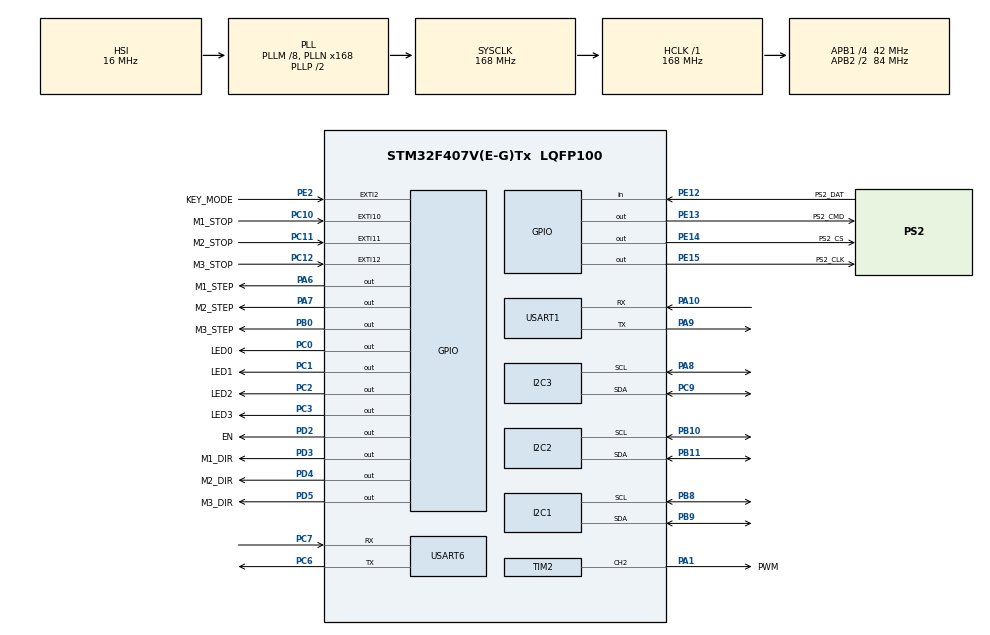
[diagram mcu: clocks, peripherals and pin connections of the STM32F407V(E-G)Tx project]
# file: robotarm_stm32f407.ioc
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I2C1.I2C_Mode=I2C_Standard
I2C2.I2C_Mode=I2C_Standard
I2C3.I2C_Mode=I2C_Standard
Mcu.Family=STM32F4
Mcu.Name=STM32F407V(E-G)Tx
Mcu.Package=LQFP100
NVIC.EXTI15_10_IRQn=true\:0\:0\:false\:false\:true\:true\:true\:true
NVIC.EXTI2_IRQn=true\:0\:0\:false\:false\:true\:true\:true\:true
NVIC.PriorityGroup=NVIC_PRIORITYGROUP_4
NVIC.TIM6_DAC_IRQn=true\:0\:0\:false\:false\:true\:true\:true\:true
NVIC.USART1_IRQn=true\:0\:0\:false\:false\:true\:true\:true\:true
PA1.GPIO_Label=PWM
PA1.Signal=S_TIM2_CH2
PA10.Mode=Asynchronous
PA10.Signal=USART1_RX
PA13.Mode=Serial_Wire
PA13.Signal=SYS_JTMS-SWDIO
PA14.Mode=Serial_Wire
PA14.Signal=SYS_JTCK-SWCLK
PA6.GPIO_Label=M1_STEP
PA6.GPIO_Speed=GPIO_SPEED_FREQ_VERY_HIGH
PA6.Signal=GPIO_Output
PA7.GPIO_Label=M2_STEP
PA7.GPIO_Speed=GPIO_SPEED_FREQ_VERY_HIGH
PA7.Signal=GPIO_Output
PA8.GPIO_Pu=GPIO_PULLUP
PA8.Mode=I2C
PA8.Signal=I2C3_SCL
PA9.Mode=Asynchronous
PA9.Signal=USART1_TX
PB0.GPIO_Label=M3_STEP
PB0.GPIO_Speed=GPIO_SPEED_FREQ_VERY_HIGH
PB0.Signal=GPIO_Output
PB10.GPIO_Pu=GPIO_PULLUP
PB10.Mode=I2C
PB10.Signal=I2C2_SCL
PB11.GPIO_Pu=GPIO_PULLUP
PB11.Mode=I2C
PB11.Signal=I2C2_SDA
PB8.GPIO_Pu=GPIO_PULLUP
PB8.Mode=I2C
PB8.Signal=I2C1_SCL
PB9.GPIO_Pu=GPIO_PULLUP
PB9.Mode=I2C
PB9.Signal=I2C1_SDA
PC0.GPIO_Label=LED0
PC0.PinState=GPIO_PIN_SET
PC0.Signal=GPIO_Output
PC1.GPIO_Label=LED1
PC1.PinState=GPIO_PIN_SET
PC1.Signal=GPIO_Output
PC10.GPIO_Label=M1_STOP
PC10.GPIO_ModeDefaultEXTI=GPIO_MODE_IT_FALLING
PC10.Signal=GPXTI10
PC11.GPIO_Label=M2_STOP
PC11.GPIO_ModeDefaultEXTI=GPIO_MODE_IT_FALLING
PC11.Signal=GPXTI11
PC12.GPIO_Label=M3_STOP
PC12.GPIO_ModeDefaultEXTI=GPIO_MODE_IT_FALLING
PC12.Signal=GPXTI12
PC2.GPIO_Label=LED2
PC2.PinState=GPIO_PIN_SET
PC2.Signal=GPIO_Output
PC3.GPIO_Label=LED3
PC3.PinState=GPIO_PIN_SET
PC3.Signal=GPIO_Output
PC6.Mode=Asynchronous
PC6.Signal=USART6_TX
PC7.Mode=Asynchronous
PC7.Signal=USART6_RX
PC9.GPIO_Pu=GPIO_PULLUP
PC9.Mode=I2C
PC9.Signal=I2C3_SDA
PD2.GPIO_Label=EN
PD2.PinState=GPIO_PIN_SET
PD2.Signal=GPIO_Output
PD3.GPIO_Label=M1_DIR
PD3.Signal=GPIO_Output
PD4.GPIO_Label=M2_DIR
PD4.Signal=GPIO_Output
PD5.GPIO_Label=M3_DIR
PD5.Signal=GPIO_Output
PE12.GPIO_Label=PS2_DAT
PE12.GPIO_PuPd=GPIO_PULLUP
PE12.Signal=GPIO_Input
PE13.GPIO_Label=PS2_CMD
PE13.GPIO_Speed=GPIO_SPEED_FREQ_HIGH
PE13.Signal=GPIO_Output
PE14.GPIO_Label=PS2_CS
PE14.GPIO_Speed=GPIO_SPEED_FREQ_HIGH
PE14.Signal=GPIO_Output
PE15.GPIO_Label=PS2_CLK
PE15.GPIO_Speed=GPIO_SPEED_FREQ_HIGH
PE15.Signal=GPIO_Output
PE2.GPIO_Label=KEY_MODE
PE2.GPIO_ModeDefaultEXTI=GPIO_MODE_IT_FALLING
PE2.GPIO_PuPd=GPIO_PULLUP
PE2.Signal=GPXTI2
PH0-OSC_IN.Mode=HSE-External-Oscillator
PH0-OSC_IN.Signal=RCC_OSC_IN
PH1-OSC_OUT.Mode=HSE-External-Oscillator
PH1-OSC_OUT.Signal=RCC_OSC_OUT
ProjectManager.HeapSize=0x200
ProjectManager.StackSize=0x400
ProjectManager.TargetToolchain=CMake
RCC.48MHZClocksFreq_Value=84000000
RCC.AHBFreq_Value=168000000
RCC.APB1CLKDivider=RCC_HCLK_DIV4
RCC.APB1Freq_Value=42000000
RCC.APB1TimFreq_Value=84000000
RCC.APB2CLKDivider=RCC_HCLK_DIV2
RCC.APB2Freq_Value=84000000
RCC.APB2TimFreq_Value=168000000
RCC.CortexFreq_Value=168000000
RCC.HCLKFreq_Value=168000000
RCC.HSE_VALUE=25000000
RCC.HSI_VALUE=16000000
RCC.LSE_VALUE=32768
RCC.PLLM=8
RCC.PLLN=168
RCC.SYSCLKFreq_VALUE=168000000
RCC.SYSCLKSource=RCC_SYSCLKSOURCE_PLLCLK
RCC.VCOOutputFreq_Value=336000000
SH.S_TIM2_CH2.0=TIM2_CH2,PWM Generation2 CH2
TIM2.Channel-PWM\ Generation2\ CH2=TIM_CHANNEL_2
TIM2.Period=20000-1
TIM2.Prescaler=84-1
TIM2.Pulse-PWM\ Generation2\ CH2=500
TIM6.AutoReloadPreload=TIM_AUTORELOAD_PRELOAD_ENABLE
TIM6.Period=20-1
TIM6.Prescaler=84-1
USART1.VirtualMode=VM_ASYNC
USART6.VirtualMode=VM_ASYNC
VP_TIM2_VS_ClockSourceINT.Mode=Internal
VP_TIM6_VS_ClockSourceINT.Mode=Enable_Timer
board=custom

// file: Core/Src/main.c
/* USER CODE BEGIN Header */
/**
  ******************************************************************************
  * @file           : main.c
  * @brief          : CubeMX startup entry point.
  ******************************************************************************
  */
/* USER CODE END Header */

#include "main.h"
#include "gpio.h"
#include "i2c.h"
#include "tim.h"
#include "usart.h"

/* USER CODE BEGIN Includes */
#include "app_init.h"
#include "app_isr_adapter.h"
/* USER CODE END Includes */

void SystemClock_Config(void);

int main(void)
{
  HAL_Init();
  SystemClock_Config();

  MX_GPIO_Init();
  MX_TIM6_Init();
  MX_USART6_UART_Init();
  MX_USART1_UART_Init();
  MX_TIM2_Init();
  MX_I2C1_Init();
  MX_I2C2_Init();
  MX_I2C3_Init();

  /* USER CODE BEGIN 2 */
  App_Init();
  /* USER CODE END 2 */

  while (1)
  {
    App_RunOnce();
  }
}

void SystemClock_Config(void)
{
  RCC_OscInitTypeDef RCC_OscInitStruct = {0};
  RCC_ClkInitTypeDef RCC_ClkInitStruct = {0};

  __HAL_RCC_PWR_CLK_ENABLE();
  __HAL_PWR_VOLTAGESCALING_CONFIG(PWR_REGULATOR_VOLTAGE_SCALE1);

  RCC_OscInitStruct.OscillatorType = RCC_OSCILLATORTYPE_HSI;
  RCC_OscInitStruct.HSIState = RCC_HSI_ON;
  RCC_OscInitStruct.HSICalibrationValue = RCC_HSICALIBRATION_DEFAULT;
  RCC_OscInitStruct.PLL.PLLState = RCC_PLL_ON;
  RCC_OscInitStruct.PLL.PLLSource = RCC_PLLSOURCE_HSI;
  RCC_OscInitStruct.PLL.PLLM = 8;
  RCC_OscInitStruct.PLL.PLLN = 168;
  RCC_OscInitStruct.PLL.PLLP = RCC_PLLP_DIV2;
  RCC_OscInitStruct.PLL.PLLQ = 4;
  if (HAL_RCC_OscConfig(&RCC_OscInitStruct) != HAL_OK)
  {
    Error_Handler();
  }

  RCC_ClkInitStruct.ClockType = RCC_CLOCKTYPE_HCLK | RCC_CLOCKTYPE_SYSCLK |
                                RCC_CLOCKTYPE_PCLK1 | RCC_CLOCKTYPE_PCLK2;
  RCC_ClkInitStruct.SYSCLKSource = RCC_SYSCLKSOURCE_PLLCLK;
  RCC_ClkInitStruct.AHBCLKDivider = RCC_SYSCLK_DIV1;
  RCC_ClkInitStruct.APB1CLKDivider = RCC_HCLK_DIV4;
  RCC_ClkInitStruct.APB2CLKDivider = RCC_HCLK_DIV2;
  if (HAL_RCC_ClockConfig(&RCC_ClkInitStruct, FLASH_LATENCY_5) != HAL_OK)
  {
    Error_Handler();
  }
}

/* USER CODE BEGIN 4 */
void HAL_TIM_PeriodElapsedCallback(TIM_HandleTypeDef *htim)
{
  App_ISR_OnTimerElapsed(htim);
}

void HAL_GPIO_EXTI_Callback(uint16_t GPIO_Pin)
{
  App_ISR_OnGpioEdge(GPIO_Pin);
}

/* USER CODE END 4 */

void Error_Handler(void)
{
  __disable_irq();
  while (1)
  {
  }
}
